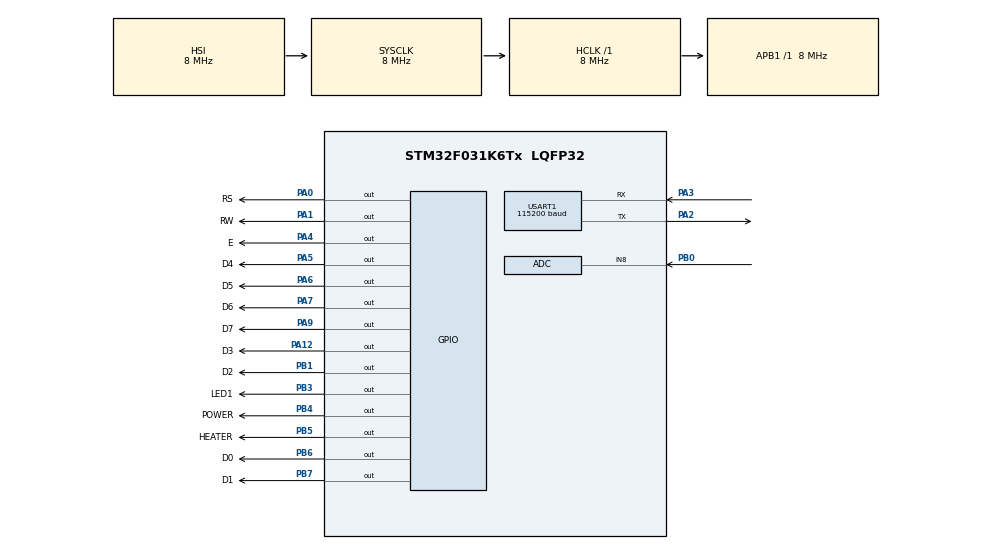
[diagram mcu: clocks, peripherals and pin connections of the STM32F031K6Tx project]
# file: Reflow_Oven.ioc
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Mcu.Family=STM32F0
Mcu.Name=STM32F031K6Tx
Mcu.Package=LQFP32
PA0.GPIO_Label=RS
PA0.GPIO_PuPd=GPIO_PULLUP
PA0.PinState=GPIO_PIN_SET
PA0.Signal=GPIO_Output
PA1.GPIO_Label=RW
PA1.Signal=GPIO_Output
PA12.GPIO_Label=D3
PA12.Signal=GPIO_Output
PA13.Mode=Serial_Wire
PA13.Signal=SYS_SWDIO
PA14.Mode=Serial_Wire
PA14.Signal=SYS_SWCLK
PA2.Mode=Asynchronous
PA2.Signal=USART1_TX
PA3.Mode=Asynchronous
PA3.Signal=USART1_RX
PA4.GPIO_Label=E
PA4.Signal=GPIO_Output
PA5.GPIO_Label=D4
PA5.Signal=GPIO_Output
PA6.GPIO_Label=D5
PA6.Signal=GPIO_Output
PA7.GPIO_Label=D6
PA7.Signal=GPIO_Output
PA9.GPIO_Label=D7
PA9.Signal=GPIO_Output
PB0.Mode=IN8
PB0.Signal=ADC_IN8
PB1.GPIO_Label=D2
PB1.Signal=GPIO_Output
PB3.GPIO_Label=LED1
PB3.Signal=GPIO_Output
PB4.GPIO_Label=POWER
PB4.Signal=GPIO_Output
PB5.GPIO_Label=HEATER
PB5.Signal=GPIO_Output
PB6.GPIO_Label=D0
PB6.Signal=GPIO_Output
PB7.GPIO_Label=D1
PB7.Signal=GPIO_Output
ProjectManager.HeapSize=0x200
ProjectManager.StackSize=0x400
ProjectManager.TargetToolchain=STM32CubeIDE
RCC.AHBFreq_Value=8000000
RCC.APB1Freq_Value=8000000
RCC.APB1TimFreq_Value=8000000
RCC.HCLKFreq_Value=8000000
RCC.SYSCLKFreq_VALUE=8000000
USART1.BaudRate=115200
USART1.VirtualMode-Asynchronous=VM_ASYNC
board=custom

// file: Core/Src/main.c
/* USER CODE BEGIN Header */
/**
  ******************************************************************************
  * @file           : main.c
  * @brief          : Main program body
  ******************************************************************************
  * @attention
  *
  * Copyright (c) 2025 STMicroelectronics.
  * All rights reserved.
  *
  * This software is licensed under terms that can be found in the LICENSE file
  * in the root directory of this software component.
  * If no LICENSE file comes with this software, it is provided AS-IS.
  *
  ******************************************************************************
  */
/* USER CODE END Header */
#include "main.h"

ADC_HandleTypeDef hadc;

UART_HandleTypeDef huart1;

void SystemClock_Config(void);
static void MX_GPIO_Init(void);
static void MX_USART1_UART_Init(void);
static void MX_ADC_Init(void);

int main(void)
{

  /* MCU Configuration--------------------------------------------------------*/

  /* Reset of all peripherals, Initializes the Flash interface and the Systick. */
  HAL_Init();

  /* Configure the system clock */
  SystemClock_Config();

  /* Initialize all configured peripherals */
  MX_GPIO_Init();
  MX_USART1_UART_Init();
  MX_ADC_Init();
  /* USER CODE BEGIN 2 */

  LCD_Init();

  /* USER CODE END 2 */

  /* Infinite loop */
  while (1)
  {

    /* USER CODE BEGIN 3 */
    uint16_t adc_value = Get_Averaged_ADC_Values(hadc, 50, 0);
    uint32_t temperature = ADC_Val_To_Temperature(adc_value, &huart1);

    Display_Temperature(temperature, &huart1);

    Display_Voltage(adc_value * 3300 / 4095, &huart1);

    FSM_Run(temperature);

    // print temperature, adc value, and voltage, and current time to UART
    char buf[100];
    snprintf(buf, sizeof(buf), "%ld,%ld,%d,%d,%ld,%d,%d\r\n", temperature, states[fsm_state_index].target_temperature_c, adc_value, adc_value * 3300 / 4095, HAL_GetTick(), fsm_state_index, heater_currently_on);
    UART_Send_String(&huart1, buf);
  }
  /* USER CODE END 3 */
}

void SystemClock_Config(void)
{
  RCC_OscInitTypeDef RCC_OscInitStruct = {0};
  RCC_ClkInitTypeDef RCC_ClkInitStruct = {0};
  RCC_PeriphCLKInitTypeDef PeriphClkInit = {0};

  /** Initializes the RCC Oscillators according to the specified parameters
  * in the RCC_OscInitTypeDef structure.
  */
  RCC_OscInitStruct.OscillatorType = RCC_OSCILLATORTYPE_HSI|RCC_OSCILLATORTYPE_HSI14;
  RCC_OscInitStruct.HSIState = RCC_HSI_ON;
  RCC_OscInitStruct.HSI14State = RCC_HSI14_ON;
  RCC_OscInitStruct.HSICalibrationValue = RCC_HSICALIBRATION_DEFAULT;
  RCC_OscInitStruct.HSI14CalibrationValue = 16;
  RCC_OscInitStruct.PLL.PLLState = RCC_PLL_NONE;
  if (HAL_RCC_OscConfig(&RCC_OscInitStruct) != HAL_OK)
  {
    Error_Handler();
  }

  /** Initializes the CPU, AHB and APB buses clocks
  */
  RCC_ClkInitStruct.ClockType = RCC_CLOCKTYPE_HCLK|RCC_CLOCKTYPE_SYSCLK
                              |RCC_CLOCKTYPE_PCLK1;
  RCC_ClkInitStruct.SYSCLKSource = RCC_SYSCLKSOURCE_HSI;
  RCC_ClkInitStruct.AHBCLKDivider = RCC_SYSCLK_DIV1;
  RCC_ClkInitStruct.APB1CLKDivider = RCC_HCLK_DIV1;

  if (HAL_RCC_ClockConfig(&RCC_ClkInitStruct, FLASH_LATENCY_0) != HAL_OK)
  {
    Error_Handler();
  }
  PeriphClkInit.PeriphClockSelection = RCC_PERIPHCLK_USART1;
  PeriphClkInit.Usart1ClockSelection = RCC_USART1CLKSOURCE_PCLK1;
  if (HAL_RCCEx_PeriphCLKConfig(&PeriphClkInit) != HAL_OK)
  {
    Error_Handler();
  }
}

static void MX_ADC_Init(void)
{

  ADC_ChannelConfTypeDef sConfig = {0};

  /** Configure the global features of the ADC (Clock, Resolution, Data Alignment and number of conversion)
  */
  hadc.Instance = ADC1;
  hadc.Init.ClockPrescaler = ADC_CLOCK_ASYNC_DIV1;
  hadc.Init.Resolution = ADC_RESOLUTION_12B;
  hadc.Init.DataAlign = ADC_DATAALIGN_RIGHT;
  hadc.Init.ScanConvMode = ADC_SCAN_DIRECTION_FORWARD;
  hadc.Init.EOCSelection = ADC_EOC_SINGLE_CONV;
  hadc.Init.LowPowerAutoWait = DISABLE;
  hadc.Init.LowPowerAutoPowerOff = DISABLE;
  hadc.Init.ContinuousConvMode = DISABLE;
  hadc.Init.DiscontinuousConvMode = DISABLE;
  hadc.Init.ExternalTrigConv = ADC_SOFTWARE_START;
  hadc.Init.ExternalTrigConvEdge = ADC_EXTERNALTRIGCONVEDGE_NONE;
  hadc.Init.DMAContinuousRequests = DISABLE;
  hadc.Init.Overrun = ADC_OVR_DATA_PRESERVED;
  if (HAL_ADC_Init(&hadc) != HAL_OK)
  {
    Error_Handler();
  }

  /** Configure for the selected ADC regular channel to be converted.
  */
  sConfig.Channel = ADC_CHANNEL_8;
  sConfig.Rank = ADC_RANK_CHANNEL_NUMBER;
  sConfig.SamplingTime = ADC_SAMPLETIME_1CYCLE_5;
  if (HAL_ADC_ConfigChannel(&hadc, &sConfig) != HAL_OK)
  {
    Error_Handler();
  }

}

static void MX_USART1_UART_Init(void)
{

  huart1.Instance = USART1;
  huart1.Init.BaudRate = 115200;
  huart1.Init.WordLength = UART_WORDLENGTH_8B;
  huart1.Init.StopBits = UART_STOPBITS_1;
  huart1.Init.Parity = UART_PARITY_NONE;
  huart1.Init.Mode = UART_MODE_TX_RX;
  huart1.Init.HwFlowCtl = UART_HWCONTROL_NONE;
  huart1.Init.OverSampling = UART_OVERSAMPLING_16;
  huart1.Init.OneBitSampling = UART_ONE_BIT_SAMPLE_DISABLE;
  huart1.AdvancedInit.AdvFeatureInit = UART_ADVFEATURE_NO_INIT;
  if (HAL_UART_Init(&huart1) != HAL_OK)
  {
    Error_Handler();
  }

}

static void MX_GPIO_Init(void)
{
  GPIO_InitTypeDef GPIO_InitStruct = {0};

  /* GPIO Ports Clock Enable */
  __HAL_RCC_GPIOA_CLK_ENABLE();
  __HAL_RCC_GPIOB_CLK_ENABLE();

  /*Configure GPIO pin Output Level */
  HAL_GPIO_WritePin(RS_GPIO_Port, RS_Pin, GPIO_PIN_SET);

  /*Configure GPIO pin Output Level */
  HAL_GPIO_WritePin(GPIOA, RW_Pin|E_Pin|D4_Pin|D5_Pin
                          |D6_Pin|D7_Pin|D3_Pin, GPIO_PIN_RESET);

  /*Configure GPIO pin Output Level */
  HAL_GPIO_WritePin(GPIOB, D2_Pin|LED1_Pin|POWER_Pin|HEATER_Pin
                          |D0_Pin|D1_Pin, GPIO_PIN_RESET);

  /*Configure GPIO pin : RS_Pin */
  GPIO_InitStruct.Pin = RS_Pin;
  GPIO_InitStruct.Mode = GPIO_MODE_OUTPUT_PP;
  GPIO_InitStruct.Pull = GPIO_PULLUP;
  GPIO_InitStruct.Speed = GPIO_SPEED_FREQ_LOW;
  HAL_GPIO_Init(RS_GPIO_Port, &GPIO_InitStruct);

  /*Configure GPIO pins : RW_Pin E_Pin D4_Pin D5_Pin
                           D6_Pin D7_Pin D3_Pin */
  GPIO_InitStruct.Pin = RW_Pin|E_Pin|D4_Pin|D5_Pin
                          |D6_Pin|D7_Pin|D3_Pin;
  GPIO_InitStruct.Mode = GPIO_MODE_OUTPUT_PP;
  GPIO_InitStruct.Pull = GPIO_NOPULL;
  GPIO_InitStruct.Speed = GPIO_SPEED_FREQ_LOW;
  HAL_GPIO_Init(GPIOA, &GPIO_InitStruct);

  /*Configure GPIO pins : D2_Pin LED1_Pin POWER_Pin HEATER_Pin
                           D0_Pin D1_Pin */
  GPIO_InitStruct.Pin = D2_Pin|LED1_Pin|POWER_Pin|HEATER_Pin
                          |D0_Pin|D1_Pin;
  GPIO_InitStruct.Mode = GPIO_MODE_OUTPUT_PP;
  GPIO_InitStruct.Pull = GPIO_NOPULL;
  GPIO_InitStruct.Speed = GPIO_SPEED_FREQ_LOW;
  HAL_GPIO_Init(GPIOB, &GPIO_InitStruct);

}

void Error_Handler(void)
{
  __disable_irq();
  while (1)
  {
  }
}
